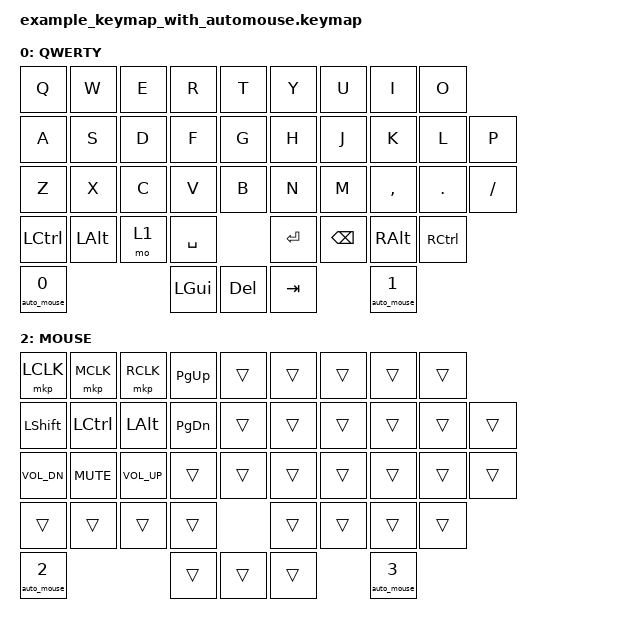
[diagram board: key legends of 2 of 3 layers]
/*
 * Example keymap demonstrating auto mouse layer functionality
 * 
 * Layer structure:
 * 0: Base layer (QWERTY)
 * 1: Lower layer (Numbers/Functions)
 * 2: Mouse layer (automatically activated by trackball movement)
 */

#include <behaviors.dtsi>
#include <dt-bindings/zmk/keys.h>
#include <dt-bindings/zmk/bt.h>
#include <dt-bindings/zmk/mouse.h>

/ {
    keymap {
        compatible = "zmk,keymap";

        // Layer 0: Base QWERTY layer
        default_layer {
            display-name = "QWERTY";
            bindings = <
                &kp Q        &kp W        &kp E        &kp R        &kp T        &kp Y        &kp U        &kp I        &kp O        
                &kp A        &kp S        &kp D        &kp F        &kp G        &kp H        &kp J        &kp K        &kp L        &kp P
                &kp Z        &kp X        &kp C        &kp V        &kp B        &kp N        &kp M        &kp COMMA    &kp DOT      &kp SLASH
                &kp LCTRL    &kp LALT              &mo 1        &kp SPC      &kp RET      &kp BSPC              &kp RALT     &kp RCTRL
                &auto_mouse 0                     &kp LGUI     &kp DEL      &kp TAB                    &auto_mouse 1
            >;
        };

        // Layer 1: Lower layer with numbers and functions
        lower_layer {
            display-name = "NUMBERS";
            bindings = <
                &kp N1       &kp N2       &kp N3       &kp N4       &kp N5       &kp N6       &kp N7       &kp N8       &kp N9
                &kp F1       &kp F2       &kp F3       &kp F4       &kp F5       &kp F6       &kp F7       &kp F8       &kp N0
                &bt BT_SEL 0 &bt BT_SEL 1 &bt BT_SEL 2 &bt BT_CLR   &trans       &kp LEFT     &kp DOWN     &kp UP       &kp RIGHT    &kp F9
                &trans       &trans                    &trans       &trans       &trans       &trans                    &trans       &trans
                &auto_mouse 2                         &trans       &trans       &trans                    &auto_mouse 3
            >;
        };

        // Layer 2: Mouse layer (automatically activated by trackball movement)
        mouse_layer {
            display-name = "MOUSE";
            bindings = <
                &mkp LCLK    &mkp MCLK    &mkp RCLK    &kp PG_UP    &trans       &trans       &trans       &trans       &trans
                &kp LSHFT    &kp LCTRL    &kp LALT     &kp PG_DN    &trans       &trans       &trans       &trans       &trans       &trans
                &kp C_VOL_DN &kp C_MUTE   &kp C_VOL_UP &trans       &trans       &trans       &trans       &trans       &trans       &trans
                &trans       &trans                    &trans       &trans       &trans       &trans                    &trans       &trans
                &auto_mouse 2                         &trans       &trans       &trans                    &auto_mouse 3
            >;
        };
    };
};

/*
 * Auto mouse behavior usage:
 * &auto_mouse 0: Toggle auto mouse enable/disable
 * &auto_mouse 1: Manually activate mouse layer
 * &auto_mouse 2: Manually deactivate mouse layer  
 * &auto_mouse 3: Reset timeout (extend mouse layer time)
 */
